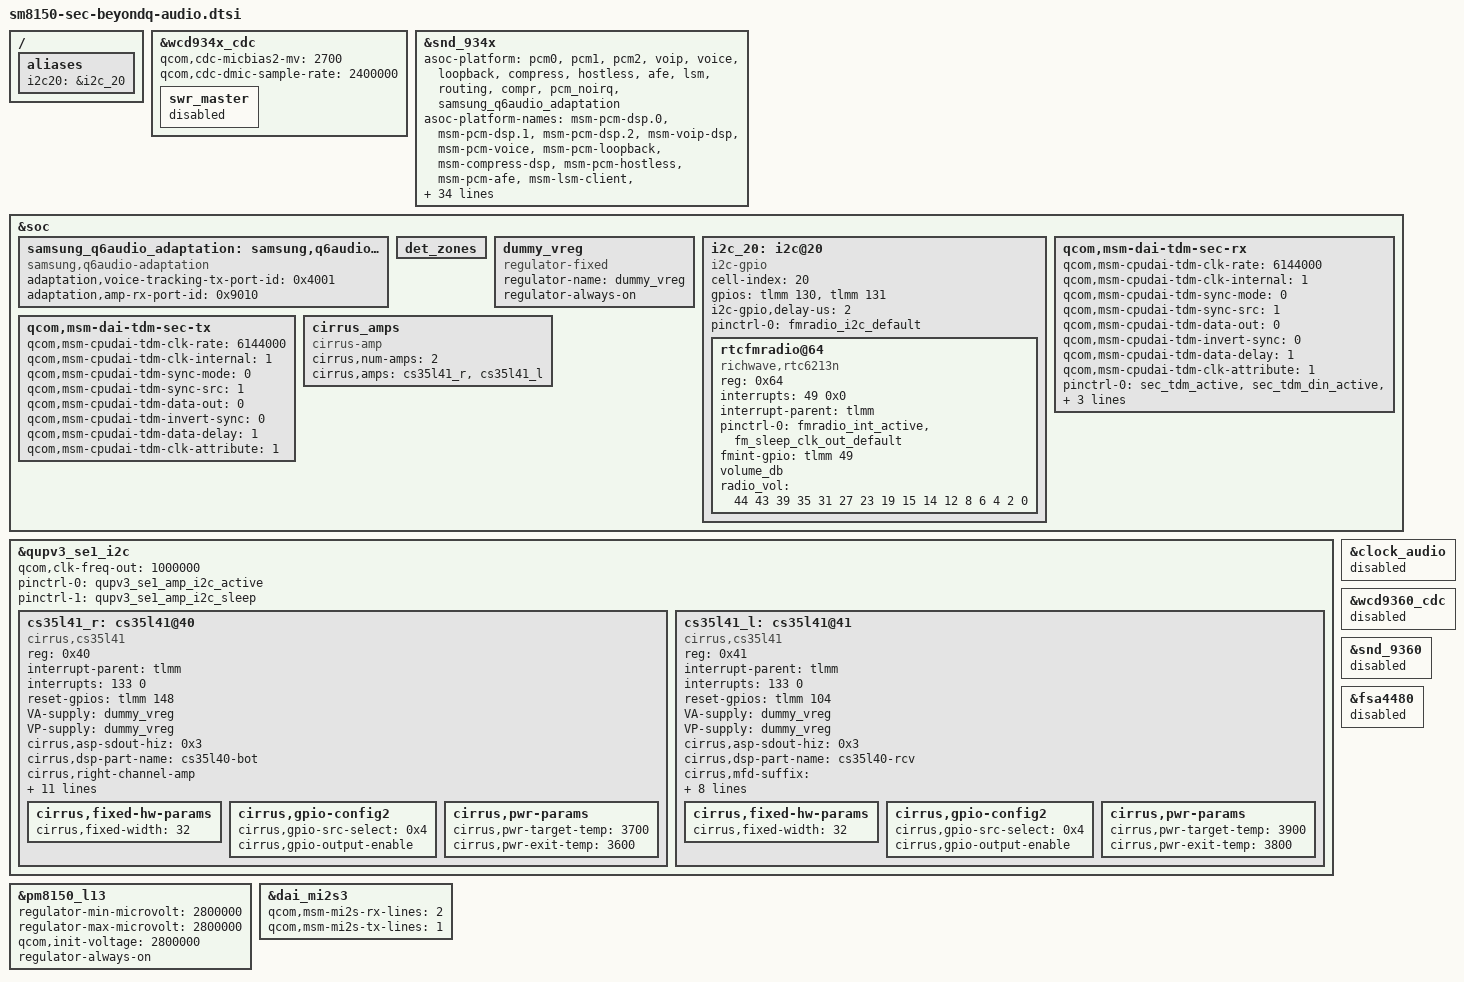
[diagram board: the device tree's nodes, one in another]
/* Copyright (c) 2016-2017, The Linux Foundation. All rights reserved.
 *
 * This program is free software; you can redistribute it and/or modify
 * it under the terms of the GNU General Public License version 2 and
 * only version 2 as published by the Free Software Foundation.
 *
 * This program is distributed in the hope that it will be useful,
 * but WITHOUT ANY WARRANTY; without even the implied warranty of
 * MERCHANTABILITY or FITNESS FOR A PARTICULAR PURPOSE.  See the
 * GNU General Public License for more details.
 */

#include "../qcom/sm8150-audio-overlay.dtsi"

/{
	aliases {
		i2c20 = &i2c_20;
	};
};

&wcd934x_cdc {
	qcom,cdc-micbias2-mv = <2700>;
	qcom,cdc-dmic-sample-rate = <2400000>;

	swr_master {
		status = "disabled";
	};
};

&snd_934x {
	asoc-platform = <&pcm0>, <&pcm1>, <&pcm2>, <&voip>, <&voice>,
			<&loopback>, <&compress>, <&hostless>,
			<&afe>, <&lsm>, <&routing>, <&compr>,
			<&pcm_noirq>, <&samsung_q6audio_adaptation>;
	asoc-platform-names = "msm-pcm-dsp.0", "msm-pcm-dsp.1",
			"msm-pcm-dsp.2", "msm-voip-dsp",
			"msm-pcm-voice", "msm-pcm-loopback",
			"msm-compress-dsp", "msm-pcm-hostless",
			"msm-pcm-afe", "msm-lsm-client",
			"msm-pcm-routing", "msm-compr-dsp",
			"msm-pcm-dsp-noirq", "q6audio-adaptation";
	qcom,audio-routing =
		"RX_BIAS", "MCLK",
		"MADINPUT", "MCLK",
		"AMIC2", "MIC BIAS2",
		"MIC BIAS2", "Headset Mic",
		"AMIC3", "MIC BIAS2",
		"MIC BIAS2", "FMLeft Tx",
		"AMIC4", "MIC BIAS2",
		"MIC BIAS2", "FMRight Tx",
		"DMIC0", "MIC BIAS1",
		"MIC BIAS1", "Digital Mic0",
		"DMIC1", "MIC BIAS1",
		"MIC BIAS1", "Digital Mic1",
		"DMIC2", "MIC BIAS3",
		"MIC BIAS3", "Digital Mic2",
		"DMIC3", "MIC BIAS3",
		"MIC BIAS3", "Digital Mic3",
		"DMIC4", "MIC BIAS4",
		"MIC BIAS4", "Digital Mic4",
		"DMIC5", "MIC BIAS4",
		"MIC BIAS4", "Digital Mic5",
		"L SPK", "Left AMP SPK",
		"R SPK", "Right AMP SPK";

	qcom,msm-mbhc-hs-mic-max-threshold-mv = <9999>;
	qcom,msm-mbhc-hs-mic-min-threshold-mv = <640>;
	qcom,wcn-btfm = <0>;
	qcom,wsa-max-devs = <0>;
	qcom,hph-en1-gpio = <0>;
	qcom,hph-en0-gpio = <0>;
	fsa4480-i2c-handle = <0>;

	pinctrl-names = "quat_mi2s_enable", "quat_mi2s_disable",
			"quat_tdm_enable", "quat_tdm_disable";
	pinctrl-0 = <&quat_mi2s_active &quat_mi2s_sd0_active
			&quat_mi2s_sd1_active>;
	pinctrl-1 = <&quat_mi2s_sleep &quat_mi2s_sd0_sleep
			&quat_mi2s_sd1_sleep>;
	pinctrl-2 = <&quat_tdm_active &quat_tdm_din_active
			&quat_tdm_dout_active>;
	pinctrl-3 = <&quat_tdm_sleep  &quat_tdm_din_sleep
			&quat_tdm_dout_sleep>;

	mbhc-button-thres = <&det_zones 13 63>,
			 <&det_zones 88 138>,
			 <&det_zones 138 138>,
			 <&det_zones 225 225>,
			 <&det_zones 450 450>,
			 <&det_zones 620 620>,
			 <&det_zones 620 620>,
			 <&det_zones 620 620>;
};

&soc {
	samsung_q6audio_adaptation: samsung,q6audio-adaptation {
		compatible = "samsung,q6audio-adaptation";
		adaptation,voice-tracking-tx-port-id = <0x4001>;
		adaptation,amp-rx-port-id = <0x9010>;
	};

	det_zones: det_zones {
		#list-det-cells = <2>;
	};

	dummy_vreg: dummy_vreg {
		compatible = "regulator-fixed";
		status = "ok";
		regulator-name = "dummy_vreg";
		regulator-always-on;
	};

	i2c_20: i2c@20{/* FM Radio (Richwave) */		
		status = "ok";

		cell-index = <20>;
		compatible = "i2c-gpio";

		gpios = <&tlmm 130 0 /* sda */
			&tlmm 131 0 /* scl */
		>;
		i2c-gpio,delay-us = <2>;
		#address-cells = <1>;
		#size-cells = <0>;

		pinctrl-names = "default";
		pinctrl-0 = <&fmradio_i2c_default>;

		rtcfmradio@64 {
			compatible = "richwave,rtc6213n", "rtc6213n";
			reg = <0x64>;
			interrupts = <49 0x0>;
			interrupt-parent = <&tlmm>;
			pinctrl-names = "default";
			pinctrl-0 = <&fmradio_int_active &fm_sleep_clk_out_default>;
			fmint-gpio = <&tlmm 49 0>; /* FM_INT */
			volume_db;
			radio_vol = <44 43 39 35 31 27 23 19
				15 14 12 8 6 4 2 0>;
		};
	};

	qcom,msm-dai-tdm-sec-rx {
		qcom,msm-cpudai-tdm-clk-rate = <6144000>;
		qcom,msm-cpudai-tdm-clk-internal = <1>;
		qcom,msm-cpudai-tdm-sync-mode = <0>;
		qcom,msm-cpudai-tdm-sync-src = <1>;
		qcom,msm-cpudai-tdm-data-out = <0>;
		qcom,msm-cpudai-tdm-invert-sync = <0>;
		qcom,msm-cpudai-tdm-data-delay = <1>;
		qcom,msm-cpudai-tdm-clk-attribute = /bits/ 16 <1>;

		pinctrl-names = "default", "sleep";
		pinctrl-0 = <&sec_tdm_active &sec_tdm_din_active
				&sec_tdm_dout_active>;
		pinctrl-1 = <&sec_tdm_sleep &sec_tdm_din_sleep
				&sec_tdm_dout_sleep>;
	};

	qcom,msm-dai-tdm-sec-tx {
		qcom,msm-cpudai-tdm-clk-rate = <6144000>;
		qcom,msm-cpudai-tdm-clk-internal = <1>;
		qcom,msm-cpudai-tdm-sync-mode = <0>;
		qcom,msm-cpudai-tdm-sync-src = <1>;
		qcom,msm-cpudai-tdm-data-out = <0>;
		qcom,msm-cpudai-tdm-invert-sync = <0>;
		qcom,msm-cpudai-tdm-data-delay = <1>;		
		qcom,msm-cpudai-tdm-clk-attribute = /bits/ 16 <1>;
	};

	cirrus_amps {
		compatible = "cirrus-amp";
		cirrus,num-amps = <2>;
		cirrus,amps = <&cs35l41_r &cs35l41_l>;
	};
};

&qupv3_se1_i2c {
	qcom,clk-freq-out = <1000000>;
	status = "ok";
	pinctrl-0 = <&qupv3_se1_amp_i2c_active>;
	pinctrl-1 = <&qupv3_se1_amp_i2c_sleep>;

	cs35l41_r: cs35l41@40 {
		#sound-dai-cells = <1>;
		compatible = "cirrus,cs35l41";
		reg = <0x40>;
		interrupt-parent = <&tlmm>;
		interrupts = <133 0>;
		reset-gpios = <&tlmm 148 0>;
		VA-supply = <&dummy_vreg>;
		VP-supply = <&dummy_vreg>;
		cirrus,asp-sdout-hiz = <0x3>;

		cirrus,dsp-part-name = "cs35l40-bot";
		cirrus,right-channel-amp;
		cirrus,mfd-suffix = "_r";
		cirrus,bd-suffix = "_right";

		cirrus,dsp-noise-gate-enable;
		cirrus,dsp-noise-gate-delay = <0x2>;
		cirrus,dsp-noise-gate-threshold = <0x6>;

		cirrus,hw-noise-gate-select = <0x3F>;
		cirrus,hw-noise-gate-delay = <0x2>;
		cirrus,hw-noise-gate-threshold = <0x6>;
		cirrus,boost-peak-milliamp = <4100>;

		pinctrl-names = "default";
		pinctrl-0 = <&cs35l41_int_active &cs35l41_rst_default>;

		cirrus,fixed-hw-params	{
			cirrus,fixed-width = <32>;
		};

		cirrus,gpio-config2 {
			cirrus,gpio-src-select = <0x4>;
			cirrus,gpio-output-enable;
		};

		cirrus,pwr-params {
			cirrus,pwr-target-temp = <3700>;
			cirrus,pwr-exit-temp = <3600>;
		};
	};

	cs35l41_l: cs35l41@41 {
		#sound-dai-cells = <1>;
		compatible = "cirrus,cs35l41";
		reg = <0x41>;
		interrupt-parent = <&tlmm>;
		interrupts = <133 0>;
		reset-gpios = <&tlmm 104 0>;
		VA-supply = <&dummy_vreg>;
		VP-supply = <&dummy_vreg>;
		cirrus,asp-sdout-hiz = <0x3>;

		cirrus,dsp-part-name = "cs35l40-rcv";
		cirrus,mfd-suffix = "";
		cirrus,bd-suffix = "_left";

		cirrus,dsp-noise-gate-enable;
		cirrus,dsp-noise-gate-delay = <0x2>;
		cirrus,dsp-noise-gate-threshold = <0x6>;

		cirrus,hw-noise-gate-select = <0x3F>;
		cirrus,hw-noise-gate-delay = <0x2>;
		cirrus,hw-noise-gate-threshold = <0x6>;
		cirrus,boost-peak-milliamp = <4100>;

		cirrus,fixed-hw-params	{
			cirrus,fixed-width = <32>;
		};

		cirrus,gpio-config2 {
			cirrus,gpio-src-select = <0x4>;
			cirrus,gpio-output-enable;
		};

		cirrus,pwr-params {
			cirrus,pwr-target-temp = <3900>;
			cirrus,pwr-exit-temp = <3800>;
		};
	};
};

&clock_audio {
	status = "disabled";
};

&pm8150_l13 {
	regulator-min-microvolt = <2800000>;
	regulator-max-microvolt = <2800000>;
	qcom,init-voltage = <2800000>;
	regulator-always-on;
};

&wcd9360_cdc {
	status = "disabled";
};

&snd_9360 {
	status = "disabled";
};

&fsa4480 {
	status = "disabled";
};

&dai_mi2s3 {
	qcom,msm-mi2s-rx-lines = <2>;
	qcom,msm-mi2s-tx-lines = <1>;
};
